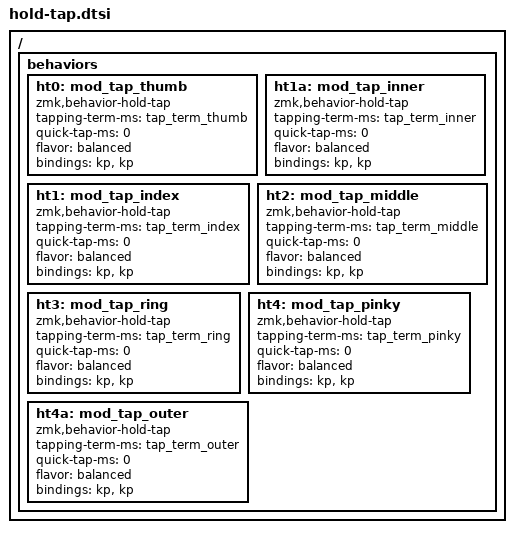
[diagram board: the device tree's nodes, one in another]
/ {
    behaviors {
        ht0: mod_tap_thumb {
            compatible = "zmk,behavior-hold-tap";
            #binding-cells = <2>;
            tapping-term-ms = <tap_term_thumb>;
            quick-tap-ms = <0>;
            flavor = "balanced";
            bindings = <&kp>, <&kp>;
        };

        ht1a: mod_tap_inner {
            compatible = "zmk,behavior-hold-tap";
            #binding-cells = <2>;
            tapping-term-ms = <tap_term_inner>;
            quick-tap-ms = <0>;
            flavor = "balanced";
            bindings = <&kp>, <&kp>;
        };

        ht1: mod_tap_index {
            compatible = "zmk,behavior-hold-tap";
            #binding-cells = <2>;
            tapping-term-ms = <tap_term_index>;
            quick-tap-ms = <0>;
            flavor = "balanced";
            bindings = <&kp>, <&kp>;
        };
        
        ht2: mod_tap_middle {
            compatible = "zmk,behavior-hold-tap";
            #binding-cells = <2>;
            tapping-term-ms = <tap_term_middle>;
            quick-tap-ms = <0>;
            flavor = "balanced";
            bindings = <&kp>, <&kp>;
        };
        
        ht3: mod_tap_ring {
            compatible = "zmk,behavior-hold-tap";
            #binding-cells = <2>;
            tapping-term-ms = <tap_term_ring>;
            quick-tap-ms = <0>;
            flavor = "balanced";
            bindings = <&kp>, <&kp>;
        };
        
        ht4: mod_tap_pinky {
            compatible = "zmk,behavior-hold-tap";
            #binding-cells = <2>;
            tapping-term-ms = <tap_term_pinky>;
            quick-tap-ms = <0>;
            flavor = "balanced";
            bindings = <&kp>, <&kp>;
        };
        
        ht4a: mod_tap_outer {
            compatible = "zmk,behavior-hold-tap";
            #binding-cells = <2>;
            tapping-term-ms = <tap_term_outer>;
            quick-tap-ms = <0>;
            flavor = "balanced";
            bindings = <&kp>, <&kp>;
        };
    };
};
